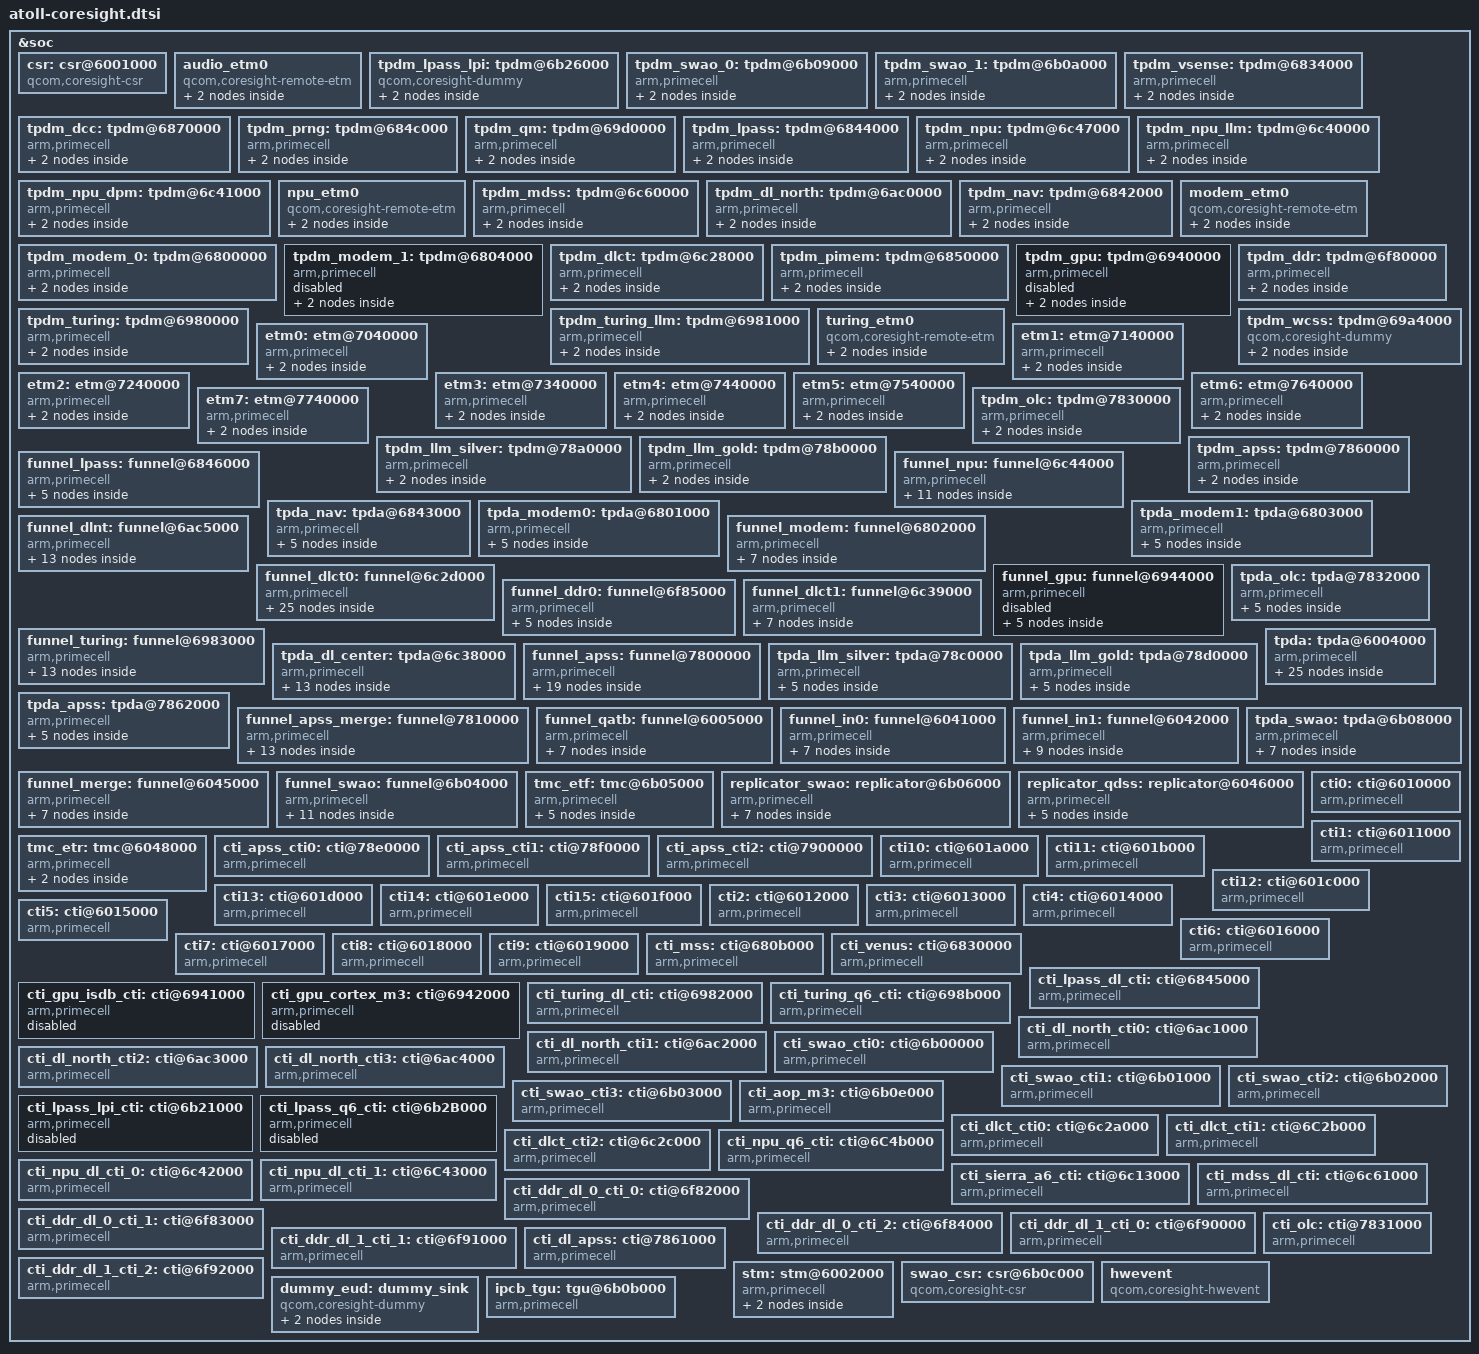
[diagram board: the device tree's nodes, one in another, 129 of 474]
/* Copyright (c) 2019, The Linux Foundation. All rights reserved.
 *
 * This program is free software; you can redistribute it and/or modify
 * it under the terms of the GNU General Public License version 2 and
 * only version 2 as published by the Free Software Foundation.
 *
 * This program is distributed in the hope that it will be useful,
 * but WITHOUT ANY WARRANTY; without even the implied warranty of
 * MERCHANTABILITY or FITNESS FOR A PARTICULAR PURPOSE.  See the
 * GNU General Public License for more details.
 */

&soc {
	csr: csr@6001000 {
		compatible = "qcom,coresight-csr";
		reg = <0x6001000 0x1000>;
		reg-names = "csr-base";

		coresight-name = "coresight-csr";

		qcom,usb-bam-support;
		qcom,hwctrl-set-support;
		qcom,set-byte-cntr-support;
		qcom,blk-size = <1>;
	};

	audio_etm0: audio_etm0 {
		compatible = "qcom,coresight-remote-etm";
		coresight-name = "coresight-audio-etm0";

		qcom,inst-id = <5>;

		port {
			audio_etm0_out_funnel_swao: endpoint {
				remote-endpoint =
				<&funnel_swao_in_audio_etm0>;
			};
		};
	};

	tpdm_lpass_lpi: tpdm@6b26000 {
		compatible = "qcom,coresight-dummy";

		coresight-name = "coresight-tpdm-lpass-lpi";
		qcom,dummy-source;

		port {
			tpdm_lpss_lpi_out_funnel_swao: endpoint {
			remote-endpoint = <&funnel_swao_in_tpdm_lpass_lpi>;
			};
		};
	};

	tpdm_swao_0: tpdm@6b09000 {
		compatible = "arm,primecell";
		arm,primecell-periphid = <0x0003b968>;
		reg = <0x6b09000 0x1000>;
		reg-names = "tpdm-base";

		coresight-name = "coresight-tpdm-swao-0";

		clocks = <&clock_aop QDSS_CLK>;
		clock-names = "apb_pclk";
		port {
			tpdm_swao_0_out_tpda_swao0: endpoint {
				remote-endpoint =
				<&tpda_swao0_in_tpdm_swao_0>;
			};
		};
	};

	tpdm_swao_1: tpdm@6b0a000 {
		compatible = "arm,primecell";
		arm,primecell-periphid = <0x0003b968>;
		reg = <0x6b0a000 0x1000>;
		reg-names = "tpdm-base";

		coresight-name = "coresight-tpdm-swao-1";

		clocks = <&clock_aop QDSS_CLK>;
		clock-names = "apb_pclk";
		port {
			tpdm_swao_1_out_tpda_swao1: endpoint {
				remote-endpoint =
				<&tpda_swao1_in_tpdm_swao_1>;
			};
		};
	};

	tpdm_vsense: tpdm@6834000 {
		compatible = "arm,primecell";
		arm,primecell-periphid = <0x0003b968>;
		reg = <0x6834000 0x1000>;
		reg-names = "tpdm-base";

		coresight-name = "coresight-tpdm-vsense";

		clocks = <&clock_aop QDSS_CLK>;
		clock-names = "apb_pclk";
		port {
			tpdm_vsense_out_tpda21: endpoint {
				remote-endpoint =
				<&tpda21_in_tpdm_vsense>;
			};
		};
	};

	tpdm_dcc: tpdm@6870000 {
		compatible = "arm,primecell";
		arm,primecell-periphid = <0x0003b968>;
		reg = <0x6870000 0x1000>;
		reg-names = "tpdm-base";

		qcom,hw-enable-check;
		coresight-name = "coresight-tpdm-dcc";

		clocks = <&clock_aop QDSS_CLK>;
		clock-names = "apb_pclk";
		port {
			tpdm_dcc_out_tpda22: endpoint {
				remote-endpoint =
				<&tpda22_in_tpdm_dcc>;
			};
		};
	};

	tpdm_prng: tpdm@684c000 {
		compatible = "arm,primecell";
		arm,primecell-periphid = <0x0003b968>;
		reg = <0x684c000 0x1000>;
		reg-names = "tpdm-base";

		coresight-name = "coresight-tpdm-prng";

		clocks = <&clock_aop QDSS_CLK>;
		clock-names = "apb_pclk";
		port {
			tpdm_prng_out_tpda23: endpoint {
				remote-endpoint =
				<&tpda23_in_tpdm_prng>;
			};
		};
	};

	tpdm_qm: tpdm@69d0000 {
		compatible = "arm,primecell";
		arm,primecell-periphid = <0x0003b968>;
		reg = <0x69d0000 0x1000>;
		reg-names = "tpdm-base";

		coresight-name = "coresight-tpdm-qm";

		clocks = <&clock_aop QDSS_CLK>;
		clock-names = "apb_pclk";
		port {
			tpdm_qm_out_tpda24: endpoint {
				remote-endpoint =
				<&tpda24_in_tpdm_qm>;
			};
		};
	};

	tpdm_lpass: tpdm@6844000 {
		compatible = "arm,primecell";
		arm,primecell-periphid = <0x0003b968>;
		reg = <0x6844000 0x1000>;
		reg-names = "tpdm-base";

		qcom,msr-fix-req;
		coresight-name = "coresight-tpdm-lpass";

		clocks = <&clock_aop QDSS_CLK>;
		clock-names = "apb_pclk";
		port {
			tpdm_lpass_out_funnel_lpass: endpoint {
				remote-endpoint =
				<&funnel_lpass_in_tpdm_lpass>;
			};
		};
	};

	tpdm_npu: tpdm@6c47000 {
		compatible = "arm,primecell";
		arm,primecell-periphid = <0x0003b968>;
		reg = <0x6c47000 0x1000>;
		reg-names = "tpdm-base";

		coresight-name = "coresight-tpdm-npu";

		clocks = <&clock_aop QDSS_CLK>;
		clock-names = "apb_pclk";
		port {
			tpdm_npu_out_funnel_npu: endpoint {
				remote-endpoint =
				<&funnel_npu_in_tpdm_npu>;
			};
		};
	};

	tpdm_npu_llm: tpdm@6c40000 {
		compatible = "arm,primecell";
		arm,primecell-periphid = <0x0003b968>;
		reg = <0x6c40000 0x1000>;
		reg-names = "tpdm-base";

		coresight-name = "coresight-tpdm-npu-llm";

		clocks = <&clock_aop QDSS_CLK>,
				<&clock_gcc GCC_NPU_AXI_CLK>,
				<&clock_gcc GCC_NPU_CFG_AHB_CLK>,
				<&clock_npucc NPU_CC_XO_CLK>,
				<&clock_npucc NPU_CC_CORE_CLK>,
				<&clock_npucc NPU_CC_CORE_CLK_SRC>;

		clock-names = "apb_pclk",
				"npu_axi_clk",
				"npu_cfg_ahb_clk",
				"npu_cc_xo_clk",
				"npu_core_clk",
				"npu_core_clk_src";

		qcom,proxy-clks = "npu_axi_clk",
				"npu_cfg_ahb_clk",
				"npu_cc_xo_clk",
				"npu_core_clk",
				"npu_core_clk_src";

		vdd-supply = <&npu_core_gdsc>;
		vdd_cx-supply = <&VDD_CX_LEVEL>;
		qcom,proxy-regs ="vdd", "vdd_cx";
		port {
			tpdm_npu_llm_out_funnel_npu: endpoint {
				remote-endpoint =
				<&funnel_npu_in_tpdm_npu_llm>;
			};
		};
	};

	tpdm_npu_dpm: tpdm@6c41000 {
		compatible = "arm,primecell";
		arm,primecell-periphid = <0x0003b968>;
		reg = <0x6c41000 0x1000>;
		reg-names = "tpdm-base";

		coresight-name = "coresight-tpdm-npu-dpm";

		clocks = <&clock_aop QDSS_CLK>;
		clock-names = "apb_pclk";
		port {
			tpdm_npu_dpm_out_funnel_npu: endpoint {
				remote-endpoint =
				<&funnel_npu_in_tpdm_npu_dpm>;
			};
		};
	};

	npu_etm0: npu_etm0 {
		compatible = "qcom,coresight-remote-etm";
		coresight-name = "coresight-npu-etm0";

		qcom,inst-id = <14>;

		port {
			npu_etm0_out_funnel_npu: endpoint {
				remote-endpoint =
				<&funnel_npu_in_npu_etm0>;
			};
		};
	};

	tpdm_mdss: tpdm@6c60000 {
		compatible = "arm,primecell";
		arm,primecell-periphid = <0x0003b968>;
		reg = <0x6c60000 0x1000>;
		reg-names = "tpdm-base";

		coresight-name = "coresight-tpdm-mdss";

		clocks = <&clock_aop QDSS_CLK>;
		clock-names = "apb_pclk";
		port {
			tpdm_mdss_out_funnel_dlnt: endpoint {
				remote-endpoint =
				<&funnel_dlnt_in_tpdm_mdss>;
			};
		};
	};

	tpdm_dl_north: tpdm@6ac0000 {
		compatible = "arm,primecell";
		arm,primecell-periphid = <0x0003b968>;
		reg = <0x6ac0000 0x1000>;
		reg-names = "tpdm-base";

		coresight-name = "coresight-tpdm-dl-north";

		clocks = <&clock_aop QDSS_CLK>;
		clock-names = "apb_pclk";
		port {
			tpdm_dl_north_out_funnel_dlnt: endpoint {
				remote-endpoint =
				<&funnel_dlnt_in_tpdm_dl_north>;
			};
		};
	};

	tpdm_nav: tpdm@6842000 {
		compatible = "arm,primecell";
		arm,primecell-periphid = <0x0003b968>;
		reg = <0x6842000 0x1000>;
		reg-names = "tpdm-base";

		coresight-name = "coresight-tpdm-nav";

		clocks = <&clock_aop QDSS_CLK>;
		clock-names = "apb_pclk";
		port {
			tpdm_nav_out_tpda_nav0: endpoint {
				remote-endpoint =
				<&tpda_nav0_in_tpdm_nav>;
			};
		};
	};

	modem_etm0: modem_etm0 {
		compatible = "qcom,coresight-remote-etm";
		coresight-name = "coresight-modem-etm0";

		qcom,inst-id = <2>;

		port {
			modem_etm0_out_funnel_dlnt: endpoint {
				remote-endpoint =
				<&funnel_dlnt_in_modem_etm0>;
			};
		};
	};

	tpdm_modem_0: tpdm@6800000 {
		compatible = "arm,primecell";
		arm,primecell-periphid = <0x0003b968>;
		reg = <0x6800000 0x1000>;
		reg-names = "tpdm-base";

		coresight-name = "coresight-tpdm-modem-0";

		clocks = <&clock_aop QDSS_CLK>;
		clock-names = "apb_pclk";
		port {
			tpdm_modem_0_out_tpda_modem0: endpoint {
				remote-endpoint =
				<&tpda_modem0_in_tpdm_modem_0>;
			};
		};
	};

	tpdm_modem_1: tpdm@6804000 {
		compatible = "arm,primecell";
		arm,primecell-periphid = <0x0003b968>;
		reg = <0x6804000 0x1000>;
		reg-names = "tpdm-base";

		status = "disabled";
		coresight-name = "coresight-tpdm-modem-1";

		clocks = <&clock_aop QDSS_CLK>;
		clock-names = "apb_pclk";
		port {
			tpdm_modem_1_out_tpda_modem1: endpoint {
				remote-endpoint =
				<&tpda_modem1_in_tpdm_modem_1>;
			};
		};
	};

	tpdm_dlct: tpdm@6c28000 {
		compatible = "arm,primecell";
		arm,primecell-periphid = <0x0003b968>;
		reg = <0x6c28000 0x1000>;
		reg-names = "tpdm-base";

		coresight-name = "coresight-tpdm-dlct";

		clocks = <&clock_aop QDSS_CLK>;
		clock-names = "apb_pclk";
		port {
			tpdm_dlct_out_funnel_dlct0: endpoint {
				remote-endpoint =
				<&funnel_dlct0_in_tpdm_dlct>;
			};
		};
	};

	tpdm_pimem: tpdm@6850000 {
		compatible = "arm,primecell";
		arm,primecell-periphid = <0x0003b968>;
		reg = <0x6850000 0x1000>;
		reg-names = "tpdm-base";

		coresight-name = "coresight-tpdm-pimem";

		clocks = <&clock_aop QDSS_CLK>;
		clock-names = "apb_pclk";
		port {
			tpdm_pimem_out_tpda_dl_center16: endpoint {
				remote-endpoint =
				<&tpda_dl_center16_in_tpdm_pimem>;
			};
		};
	};

	tpdm_gpu: tpdm@6940000 {
		compatible = "arm,primecell";
		arm,primecell-periphid = <0x0003b968>;
		reg = <0x6940000 0x1000>;
		reg-names = "tpdm-base";

		coresight-name = "coresight-tpdm-gpu";
		status = "disabled";

		clocks = <&clock_aop QDSS_CLK>;
		clock-names = "apb_pclk";
		port {
			tpdm_gpu_out_funnel_gpu: endpoint {
				remote-endpoint =
				<&funnel_gpu_in_tpdm_gpu>;
			};
		};
	};

	tpdm_ddr: tpdm@6f80000 {
		compatible = "arm,primecell";
		arm,primecell-periphid = <0x0003b968>;
		reg = <0x6f80000 0x1000>;
		reg-names = "tpdm-base";

		coresight-name = "coresight-tpdm-ddr";
		qcom,msr-fix-req;

		clocks = <&clock_aop QDSS_CLK>;
		clock-names = "apb_pclk";
		port {
			tpdm_ddr_out_funnel_ddr0: endpoint {
				remote-endpoint =
				<&funnel_ddr0_in_tpdm_ddr>;
			};
		};
	};

	tpdm_turing: tpdm@6980000 {
		compatible = "arm,primecell";
		arm,primecell-periphid = <0x0003b968>;
		reg = <0x6980000 0x1000>;
		reg-names = "tpdm-base";

		coresight-name = "coresight-tpdm-turing";

		clocks = <&clock_aop QDSS_CLK>;
		clock-names = "apb_pclk";
		port {
			tpdm_turing_out_funnel_turing: endpoint {
				remote-endpoint =
				<&funnel_turing_in_tpdm_turing>;
			};
		};
	};

	tpdm_turing_llm: tpdm@6981000 {
		compatible = "arm,primecell";
		arm,primecell-periphid = <0x0003b968>;
		reg = <0x6981000 0x1000>;
		reg-names = "tpdm-base";

		coresight-name = "coresight-tpdm-turing-llm";

		clocks = <&clock_aop QDSS_CLK>;
		clock-names = "apb_pclk";
		port {
			tpdm_turing_llm_out_funnel_turing: endpoint {
				remote-endpoint =
				<&funnel_turing_in_tpdm_turing_llm>;
			};
		};
	};

	turing_etm0: turing_etm0 {
		compatible = "qcom,coresight-remote-etm";
		coresight-name = "coresight-turing-etm0";

		qcom,inst-id = <13>;

		port {
			turing_etm0_out_funnel_turing: endpoint {
				remote-endpoint =
				<&funnel_turing_in_turing_etm0>;
			};
		};
	};

	tpdm_wcss: tpdm@69a4000 {
		compatible = "qcom,coresight-dummy";

		coresight-name = "coresight-tpdm-wcss";
		qcom,dummy-source;

		port {
			tpdm_wcss_out_funnel_in1: endpoint {
				remote-endpoint =
				<&funnel_in1_in_tpdm_wcss>;
			};
		};
	};

	etm0: etm@7040000 {
		compatible = "arm,primecell";
		arm,primecell-periphid = <0x000bb95d>;
		reg = <0x7040000 0x1000>;
		cpu = <&CPU0>;

		coresight-name = "coresight-etm0";

		qcom,tupwr-disable;
		clocks = <&clock_aop QDSS_CLK>;
		clock-names = "apb_pclk";
		port {
			etm0_out_funnel_apss: endpoint {
				remote-endpoint =
				<&funnel_apss_in_etm0>;
			};
		};
	};

	etm1: etm@7140000 {
		compatible = "arm,primecell";
		arm,primecell-periphid = <0x000bb95d>;
		reg = <0x7140000 0x1000>;
		cpu = <&CPU1>;

		coresight-name = "coresight-etm1";

		qcom,tupwr-disable;
		clocks = <&clock_aop QDSS_CLK>;
		clock-names = "apb_pclk";
		port {
			etm1_out_funnel_apss: endpoint {
				remote-endpoint =
				<&funnel_apss_in_etm1>;
			};
		};
	};

	etm2: etm@7240000 {
		compatible = "arm,primecell";
		arm,primecell-periphid = <0x000bb95d>;
		reg = <0x7240000 0x1000>;
		cpu = <&CPU2>;

		qcom,tupwr-disable;
		coresight-name = "coresight-etm2";

		clocks = <&clock_aop QDSS_CLK>;
		clock-names = "apb_pclk";
		port {
			etm2_out_funnel_apss: endpoint {
				remote-endpoint =
				<&funnel_apss_in_etm2>;
			};
		};
	};

	etm3: etm@7340000 {
		compatible = "arm,primecell";
		arm,primecell-periphid = <0x000bb95d>;
		reg = <0x7340000 0x1000>;
		cpu = <&CPU3>;

		qcom,tupwr-disable;
		coresight-name = "coresight-etm3";

		clocks = <&clock_aop QDSS_CLK>;
		clock-names = "apb_pclk";
		port {
			etm3_out_funnel_apss: endpoint {
				remote-endpoint =
				<&funnel_apss_in_etm3>;
			};
		};
	};

	etm4: etm@7440000 {
		compatible = "arm,primecell";
		arm,primecell-periphid = <0x000bb95d>;
		reg = <0x7440000 0x1000>;
		cpu = <&CPU4>;

		coresight-name = "coresight-etm4";

		qcom,tupwr-disable;
		clocks = <&clock_aop QDSS_CLK>;
		clock-names = "apb_pclk";
		port {
			etm4_out_funnel_apss: endpoint {
				remote-endpoint =
				<&funnel_apss_in_etm4>;
			};
		};
	};

	etm5: etm@7540000 {
		compatible = "arm,primecell";
		arm,primecell-periphid = <0x000bb95d>;
		reg = <0x7540000 0x1000>;
		cpu = <&CPU5>;

		coresight-name = "coresight-etm5";

		qcom,tupwr-disable;
		clocks = <&clock_aop QDSS_CLK>;
		clock-names = "apb_pclk";
		port {
			etm5_out_funnel_apss: endpoint {
				remote-endpoint =
				<&funnel_apss_in_etm5>;
			};
		};
	};

	etm6: etm@7640000 {
		compatible = "arm,primecell";
		arm,primecell-periphid = <0x000bb95d>;
		reg = <0x7640000 0x1000>;
		cpu = <&CPU6>;

		coresight-name = "coresight-etm6";

		qcom,tupwr-disable;
		clocks = <&clock_aop QDSS_CLK>;
		clock-names = "apb_pclk";
		port {
			etm6_out_funnel_apss: endpoint {
				remote-endpoint =
				<&funnel_apss_in_etm6>;
			};
		};
	};

	etm7: etm@7740000 {
		compatible = "arm,primecell";
		arm,primecell-periphid = <0x000bb95d>;
		reg = <0x7740000 0x1000>;
		cpu = <&CPU7>;

		coresight-name = "coresight-etm7";

		qcom,tupwr-disable;
		clocks = <&clock_aop QDSS_CLK>;
		clock-names = "apb_pclk";
		port {
			etm7_out_funnel_apss: endpoint {
				remote-endpoint =
				<&funnel_apss_in_etm7>;
			};
		};
	};

	tpdm_olc: tpdm@7830000 {
		compatible = "arm,primecell";
		arm,primecell-periphid = <0x0003b968>;
		reg = <0x7830000 0x1000>;
		reg-names = "tpdm-base";

		coresight-name = "coresight-tpdm-olc";

		clocks = <&clock_aop QDSS_CLK>;
		clock-names = "apb_pclk";
		port {
			tpdm_olc_out_tpda_olc0: endpoint {
				remote-endpoint =
				<&tpda_olc0_in_tpdm_olc>;
			};
		};
	};

	tpdm_llm_silver: tpdm@78a0000 {
		compatible = "arm,primecell";
		arm,primecell-periphid = <0x0003b968>;
		reg = <0x78a0000 0x1000>;
		reg-names = "tpdm-base";

		coresight-name = "coresight-tpdm-llm-silver";

		clocks = <&clock_aop QDSS_CLK>;
		clock-names = "apb_pclk";
		port {
			tpdm_llm_silver_out_tpda_llm_silver0: endpoint {
				remote-endpoint =
				<&tpda_llm_silver0_in_tpdm_llm_silver>;
			};
		};
	};

	tpdm_llm_gold: tpdm@78b0000 {
		compatible = "arm,primecell";
		arm,primecell-periphid = <0x0003b968>;
		reg = <0x78b0000 0x1000>;
		reg-names = "tpdm-base";

		coresight-name = "coresight-tpdm-llm-gold";

		clocks = <&clock_aop QDSS_CLK>;
		clock-names = "apb_pclk";
		port {
			tpdm_llm_gold_out_tpda_llm_gold0: endpoint {
				remote-endpoint =
				<&tpda_llm_gold0_in_tpdm_llm_gold>;
			};
		};
	};

	tpdm_apss: tpdm@7860000 {
		compatible = "arm,primecell";
		arm,primecell-periphid = <0x0003b968>;
		reg = <0x7860000 0x1000>;
		reg-names = "tpdm-base";

		coresight-name = "coresight-tpdm-apss";

		clocks = <&clock_aop QDSS_CLK>;
		clock-names = "apb_pclk";
		port {
			tpdm_apss_out_tpda_apss0: endpoint {
				remote-endpoint =
				<&tpda_apss0_in_tpdm_apss>;
			};
		};
	};

	funnel_lpass: funnel@6846000 {
		compatible = "arm,primecell";
		arm,primecell-periphid = <0x0003b908>;
		reg = <0x6846000 0x1000>;
		reg-names = "funnel-base";

		coresight-name = "coresight-funnel-lpass";

		clocks = <&clock_aop QDSS_CLK>;
		clock-names = "apb_pclk";
		ports {
			#address-cells = <1>;
			#size-cells = <0>;
			port@0 {
				reg = <0>;
				funnel_lpass_out_funnel_dlct0: endpoint {
					remote-endpoint =
					<&funnel_dlct0_in_funnel_lpass>;
				};
			};

			port@1 {
				reg = <0>;
				funnel_lpass_in_tpdm_lpass: endpoint {
					slave-mode;
					remote-endpoint =
					<&tpdm_lpass_out_funnel_lpass>;
				};
			};

		};
	};

	funnel_npu: funnel@6c44000 {
		compatible = "arm,primecell";
		arm,primecell-periphid = <0x0003b908>;
		reg = <0x6c44000 0x1000>;
		reg-names = "funnel-base";

		coresight-name = "coresight-funnel-npu";

		clocks = <&clock_aop QDSS_CLK>;
		clock-names = "apb_pclk";
		ports {
			#address-cells = <1>;
			#size-cells = <0>;
			port@0 {
				reg = <0>;
				funnel_npu_out_funnel_dlct0: endpoint {
					remote-endpoint =
					<&funnel_dlct0_in_funnel_npu>;
				};
			};

			port@1 {
				reg = <0>;
				funnel_npu_in_tpdm_npu: endpoint {
					slave-mode;
					remote-endpoint =
					<&tpdm_npu_out_funnel_npu>;
				};
			};

			port@2 {
				reg = <1>;
				funnel_npu_in_tpdm_npu_llm: endpoint {
					slave-mode;
					remote-endpoint =
					<&tpdm_npu_llm_out_funnel_npu>;
				};
			};

			port@3 {
				reg = <2>;
				funnel_npu_in_tpdm_npu_dpm: endpoint {
					slave-mode;
					remote-endpoint =
					<&tpdm_npu_dpm_out_funnel_npu>;
				};
			};

			port@4 {
				reg = <3>;
				funnel_npu_in_npu_etm0: endpoint {
					slave-mode;
					remote-endpoint =
					<&npu_etm0_out_funnel_npu>;
				};
			};

		};
	};

	tpda_nav: tpda@6843000 {
		compatible = "arm,primecell";
		arm,primecell-periphid = <0x0003b969>;
		reg = <0x6843000 0x1000>;
		reg-names = "tpda-base";

		coresight-name = "coresight-tpda-nav";
		qcom,tpda-atid = <68>;
		qcom,cmb-elem-size = <0 32>;

		clocks = <&clock_aop QDSS_CLK>;
		clock-names = "apb_pclk";
		ports {
			#address-cells = <1>;
			#size-cells = <0>;
			port@0 {
				reg = <0>;
				tpda_nav_out_funnel_dlnt: endpoint {
					remote-endpoint =
					<&funnel_dlnt_in_tpda_nav>;
				};
			};

			port@1 {
				reg = <0>;
				tpda_nav0_in_tpdm_nav: endpoint {
					slave-mode;
					remote-endpoint =
					<&tpdm_nav_out_tpda_nav0>;
				};
			};

		};
	};

	tpda_modem0: tpda@6801000 {
		compatible = "arm,primecell";
		arm,primecell-periphid = <0x0003b969>;
		reg = <0x6801000 0x1000>;
		reg-names = "tpda-base";

		coresight-name = "coresight-tpda-modem0";
		qcom,tpda-atid = <67>;
		qcom,dsb-elem-size = <0 32>;
		qcom,cmb-elem-size = <0 64>;

		clocks = <&clock_aop QDSS_CLK>;
		clock-names = "apb_pclk";
		ports {
			#address-cells = <1>;
			#size-cells = <0>;
			port@0 {
				reg = <0>;
				tpda_modem0_out_funnel_modem: endpoint {
					remote-endpoint =
					<&funnel_modem_in_tpda_modem0>;
				};
			};

			port@1 {
				reg = <0>;
				tpda_modem0_in_tpdm_modem_0: endpoint {
					slave-mode;
					remote-endpoint =
					<&tpdm_modem_0_out_tpda_modem0>;
				};
			};

		};
	};

	tpda_modem1: tpda@6803000 {
		compatible = "arm,primecell";
		arm,primecell-periphid = <0x0003b969>;
		reg = <0x6803000 0x1000>;
		reg-names = "tpda-base";

		coresight-name = "coresight-tpda-modem1";
		qcom,tpda-atid = <98>;
		qcom,dsb-elem-size = <0 32>;
		qcom,cmb-elem-size = <0 64>;

		clocks = <&clock_aop QDSS_CLK>;
		clock-names = "apb_pclk";
		ports {
			#address-cells = <1>;
			#size-cells = <0>;
			port@0 {
				reg = <0>;
				tpda_modem1_out_funnel_modem: endpoint {
					remote-endpoint =
					<&funnel_modem_in_tpda_modem1>;
				};
			};

			port@1 {
				reg = <0>;
				tpda_modem1_in_tpdm_modem_1: endpoint {
					slave-mode;
					remote-endpoint =
					<&tpdm_modem_1_out_tpda_modem1>;
				};
			};

		};
	};

	funnel_modem: funnel@6802000 {
		compatible = "arm,primecell";
		arm,primecell-periphid = <0x0003b908>;
		reg = <0x6802000 0x1000>;
		reg-names = "funnel-base";

		coresight-name = "coresight-funnel-modem";

		clocks = <&clock_aop QDSS_CLK>;
		clock-names = "apb_pclk";
		ports {
			#address-cells = <1>;
			#size-cells = <0>;
			port@0 {
				reg = <0>;
				funnel_modem_out_funnel_dlnt: endpoint {
					remote-endpoint =
					<&funnel_dlnt_in_funnel_modem>;
				};
			};

			port@1 {
				reg = <0>;
				funnel_modem_in_tpda_modem0: endpoint {
					slave-mode;
					remote-endpoint =
					<&tpda_modem0_out_funnel_modem>;
				};
			};

			port@2 {
				reg = <1>;
				funnel_modem_in_tpda_modem1: endpoint {
					slave-mode;
					remote-endpoint =
					<&tpda_modem1_out_funnel_modem>;
				};
			};

		};
	};

	funnel_dlnt: funnel@6ac5000 {
		compatible = "arm,primecell";
		arm,primecell-periphid = <0x0003b908>;
		reg = <0x6ac5000 0x1000>;
		reg-names = "funnel-base";

		coresight-name = "coresight-funnel-dlnt";

		clocks = <&clock_aop QDSS_CLK>;
		clock-names = "apb_pclk";
		ports {
			#address-cells = <1>;
			#size-cells = <0>;
			port@0 {
				reg = <0>;
				funnel_dlnt_out_funnel_dlct0: endpoint {
					remote-endpoint =
					<&funnel_dlct0_in_funnel_dlnt>;
				};
			};

			port@1 {
				reg = <0>;
				funnel_dlnt_in_tpdm_mdss: endpoint {
					slave-mode;
					remote-endpoint =
					<&tpdm_mdss_out_funnel_dlnt>;
				};
			};

			port@2 {
				reg = <1>;
				funnel_dlnt_in_tpdm_dl_north: endpoint {
					slave-mode;
					remote-endpoint =
					<&tpdm_dl_north_out_funnel_dlnt>;
				};
			};

			port@3 {
				reg = <2>;
				funnel_dlnt_in_tpda_nav: endpoint {
					slave-mode;
					remote-endpoint =
					<&tpda_nav_out_funnel_dlnt>;
				};
			};

			port@4 {
				reg = <5>;
				funnel_dlnt_in_modem_etm0: endpoint {
					slave-mode;
					remote-endpoint =
					<&modem_etm0_out_funnel_dlnt>;
				};
			};

			port@5 {
				reg = <6>;
				funnel_dlnt_in_funnel_modem: endpoint {
					slave-mode;
					remote-endpoint =
					<&funnel_modem_out_funnel_dlnt>;
				};
			};

		};
	};

	funnel_dlct0: funnel@6c2d000 {
		compatible = "arm,primecell";
		arm,primecell-periphid = <0x0003b908>;
		reg = <0x6c2d000 0x1000>;
		reg-names = "funnel-base";

		coresight-name = "coresight-funnel-dlct0";

		clocks = <&clock_aop QDSS_CLK>;
		clock-names = "apb_pclk";
		ports {
			#address-cells = <1>;
			#size-cells = <0>;
			port@0 {
				reg = <0>;
				funnel_dlct0_out_tpda2: endpoint {
					remote-endpoint =
					<&tpda2_in_funnel_dlct0>;
					source = <&tpdm_lpass>;
				};
			};

			port@1 {
				reg = <0>;
				funnel_dlct0_out_tpda11: endpoint {
					remote-endpoint =
					<&tpda11_in_funnel_dlct0>;
					source = <&tpdm_npu>;
				};
			};

			port@2 {
				reg = <0>;
				funnel_dlct0_out_tpda12: endpoint {
					remote-endpoint =
					<&tpda12_in_funnel_dlct0>;
					source = <&tpdm_npu_llm>;
				};
			};

			port@3 {
				reg = <0>;
				funnel_dlct0_out_tpda13: endpoint {
					remote-endpoint =
					<&tpda13_in_funnel_dlct0>;
					source = <&tpdm_npu_dpm>;
				};
			};

			port@4 {
				reg = <0>;
				funnel_dlct0_out_tpda14: endpoint {
					remote-endpoint =
					<&tpda14_in_funnel_dlct0>;
					source = <&tpdm_mdss>;
				};
			};

			port@5 {
				reg = <0>;
				funnel_dlct0_out_tpda15: endpoint {
					remote-endpoint =
					<&tpda15_in_funnel_dlct0>;
					source = <&tpdm_dl_north>;
				};
			};

			port@6 {
				reg = <0>;
				funnel_dlct0_out_tpda19: endpoint {
					remote-endpoint =
					<&tpda19_in_funnel_dlct0>;
					source = <&tpdm_dlct>;
				};
			};

			port@7 {
				reg = <0>;
				funnel_dlct0_out_funnel_qatb: endpoint {
					remote-endpoint =
					<&funnel_qatb_in_funnel_dlct0>;
				};
			};

			port@8 {
				reg = <0>;
				funnel_dlct0_in_funnel_lpass: endpoint {
					slave-mode;
					remote-endpoint =
					<&funnel_lpass_out_funnel_dlct0>;
				};
			};

			port@9 {
				reg = <4>;
				funnel_dlct0_in_funnel_npu: endpoint {
					slave-mode;
					remote-endpoint =
					<&funnel_npu_out_funnel_dlct0>;
				};
			};

			port@10 {
				reg = <5>;
				funnel_dlct0_in_funnel_dlnt: endpoint {
					slave-mode;
					remote-endpoint =
					<&funnel_dlnt_out_funnel_dlct0>;
				};
			};

			port@11 {
				reg = <6>;
				funnel_dlct0_in_tpdm_dlct: endpoint {
					slave-mode;
					remote-endpoint =
					<&tpdm_dlct_out_funnel_dlct0>;
				};
			};

		};
	};

	funnel_gpu: funnel@6944000 {
		compatible = "arm,primecell";
		arm,primecell-periphid = <0x0003b908>;
		reg = <0x6944000 0x1000>;
		reg-names = "funnel-base";

		coresight-name = "coresight-funnel-gpu";
		status = "disabled";

		clocks = <&clock_aop QDSS_CLK>;
		clock-names = "apb_pclk";
		ports {
			#address-cells = <1>;
			#size-cells = <0>;
			port@0 {
				reg = <0>;
				funnel_gpu_out_tpda_dl_center: endpoint {
					remote-endpoint =
					<&tpda_dl_center_in_funnel_gpu>;
				};
			};

			port@1 {
				reg = <0>;
				funnel_gpu_in_tpdm_gpu: endpoint {
					slave-mode;
					remote-endpoint =
					<&tpdm_gpu_out_funnel_gpu>;
				};
			};

		};
	};

	funnel_ddr0: funnel@6f85000 {
		compatible = "arm,primecell";
		arm,primecell-periphid = <0x0003b908>;
		reg = <0x6f85000 0x1000>;
		reg-names = "funnel-base";

		coresight-name = "coresight-funnel-ddr0";

		clocks = <&clock_aop QDSS_CLK>;
		clock-names = "apb_pclk";
		ports {
			#address-cells = <1>;
			#size-cells = <0>;
			port@0 {
				reg = <0>;
				funnel_ddr0_out_tpda_dl_center: endpoint {
					remote-endpoint =
					<&tpda_dl_center_in_funnel_ddr0>;
				};
			};

			port@1 {
				reg = <0>;
				funnel_ddr0_in_tpdm_ddr: endpoint {
					slave-mode;
					remote-endpoint =
					<&tpdm_ddr_out_funnel_ddr0>;
				};
			};

		};
	};

	funnel_turing: funnel@6983000 {
		compatible = "arm,primecell";
		arm,primecell-periphid = <0x0003b908>;
		reg = <0x6983000 0x1000>;
		reg-names = "funnel-base";

		coresight-name = "coresight-funnel-turing";

		clocks = <&clock_aop QDSS_CLK>;
		clock-names = "apb_pclk";
		ports {
			#address-cells = <1>;
			#size-cells = <0>;
			port@0 {
				reg = <0>;
				funnel_turing_out_tpda_dl_center5: endpoint {
					remote-endpoint =
					<&tpda_dl_center5_in_funnel_turing>;
					source = <&tpdm_turing>;
				};
			};

			port@1 {
				reg = <0>;
				funnel_turing_out_tpda_dl_center6: endpoint {
					remote-endpoint =
					<&tpda_dl_center6_in_funnel_turing>;
					source = <&tpdm_turing_llm>;
				};
			};

			port@2 {
				reg = <0>;
				funnel_turing_out_funnel_dlct1: endpoint {
					remote-endpoint =
					<&funnel_dlct1_in_funnel_turing>;
				};
			};

			port@3 {
				reg = <0>;
				funnel_turing_in_tpdm_turing: endpoint {
					slave-mode;
					remote-endpoint =
					<&tpdm_turing_out_funnel_turing>;
				};
			};

			port@4 {
				reg = <1>;
				funnel_turing_in_tpdm_turing_llm: endpoint {
					slave-mode;
					remote-endpoint =
					<&tpdm_turing_llm_out_funnel_turing>;
				};
			};

			port@5 {
				reg = <2>;
				funnel_turing_in_turing_etm0: endpoint {
					slave-mode;
					remote-endpoint =
					<&turing_etm0_out_funnel_turing>;
				};
			};

		};
	};

	tpda_dl_center: tpda@6c38000 {
		compatible = "arm,primecell";
		arm,primecell-periphid = <0x0003b969>;
		reg = <0x6c38000 0x1000>;
		reg-names = "tpda-base";

		coresight-name = "coresight-tpda-dl-center";
		qcom,tpda-atid = <78>;
		qcom,dsb-elem-size = <0 32>,
				     <3 32>,
				     <5 32>,
				     <16 32>;
		qcom,cmb-elem-size = <3 32>,
				     <6 32>,
				     <16 64>;

		clocks = <&clock_aop QDSS_CLK>;
		clock-names = "apb_pclk";
		ports {
			#address-cells = <1>;
			#size-cells = <0>;
			port@0 {
				reg = <0>;
				tpda_dl_center_out_funnel_dlct1: endpoint {
					remote-endpoint =
					<&funnel_dlct1_in_tpda_dl_center>;
				};
			};

			port@1 {
				reg = <16>;
				tpda_dl_center16_in_tpdm_pimem: endpoint {
					slave-mode;
					remote-endpoint =
					<&tpdm_pimem_out_tpda_dl_center16>;
				};
			};

			port@2 {
				reg = <0>;
				tpda_dl_center_in_funnel_gpu: endpoint {
					slave-mode;
					remote-endpoint =
					<&funnel_gpu_out_tpda_dl_center>;
				};
			};

			port@3 {
				reg = <3>;
				tpda_dl_center_in_funnel_ddr0: endpoint {
					slave-mode;
					remote-endpoint =
					<&funnel_ddr0_out_tpda_dl_center>;
				};
			};

			port@4 {
				reg = <5>;
				tpda_dl_center5_in_funnel_turing: endpoint {
					slave-mode;
					remote-endpoint =
					<&funnel_turing_out_tpda_dl_center5>;
				};
			};

			port@5 {
				reg = <6>;
				tpda_dl_center6_in_funnel_turing: endpoint {
					slave-mode;
					remote-endpoint =
					<&funnel_turing_out_tpda_dl_center6>;
				};
			};

		};
	};

	funnel_dlct1: funnel@6c39000 {
		compatible = "arm,primecell";
		arm,primecell-periphid = <0x0003b908>;
		reg = <0x6c39000 0x1000>;
		reg-names = "funnel-base";

		coresight-name = "coresight-funnel-dlct1";

		clocks = <&clock_aop QDSS_CLK>;
		clock-names = "apb_pclk";
		ports {
			#address-cells = <1>;
			#size-cells = <0>;
			port@0 {
				reg = <0>;
				funnel_dlct1_out_funnel_in1: endpoint {
					remote-endpoint =
					<&funnel_in1_in_funnel_dlct1>;
				};
			};

			port@1 {
				reg = <0>;
				funnel_dlct1_in_tpda_dl_center: endpoint {
					slave-mode;
					remote-endpoint =
					<&tpda_dl_center_out_funnel_dlct1>;
				};
			};

			port@2 {
				reg = <4>;
				funnel_dlct1_in_funnel_turing: endpoint {
					slave-mode;
					remote-endpoint =
					<&funnel_turing_out_funnel_dlct1>;
				};
			};

		};
	};

	funnel_apss: funnel@7800000 {
		compatible = "arm,primecell";
		arm,primecell-periphid = <0x0003b908>;
		reg = <0x7800000 0x1000>;
		reg-names = "funnel-base";

		coresight-name = "coresight-funnel-apss";

		clocks = <&clock_aop QDSS_CLK>;
		clock-names = "apb_pclk";
		ports {
			#address-cells = <1>;
			#size-cells = <0>;
			port@0 {
				reg = <0>;
				funnel_apss_out_funnel_apss_merge: endpoint {
					remote-endpoint =
					<&funnel_apss_merge_in_funnel_apss>;
				};
			};

			port@1 {
				reg = <0>;
				funnel_apss_in_etm0: endpoint {
					slave-mode;
					remote-endpoint =
					<&etm0_out_funnel_apss>;
				};
			};

			port@2 {
				reg = <1>;
				funnel_apss_in_etm1: endpoint {
					slave-mode;
					remote-endpoint =
					<&etm1_out_funnel_apss>;
				};
			};

			port@3 {
				reg = <2>;
				funnel_apss_in_etm2: endpoint {
					slave-mode;
					remote-endpoint =
					<&etm2_out_funnel_apss>;
				};
			};

			port@4 {
				reg = <3>;
				funnel_apss_in_etm3: endpoint {
					slave-mode;
					remote-endpoint =
					<&etm3_out_funnel_apss>;
				};
			};

			port@5 {
				reg = <4>;
				funnel_apss_in_etm4: endpoint {
					slave-mode;
					remote-endpoint =
					<&etm4_out_funnel_apss>;
				};
			};

			port@6 {
				reg = <5>;
				funnel_apss_in_etm5: endpoint {
					slave-mode;
					remote-endpoint =
					<&etm5_out_funnel_apss>;
				};
			};

			port@7 {
				reg = <6>;
				funnel_apss_in_etm6: endpoint {
					slave-mode;
					remote-endpoint =
					<&etm6_out_funnel_apss>;
				};
			};

			port@8 {
				reg = <7>;
				funnel_apss_in_etm7: endpoint {
					slave-mode;
					remote-endpoint =
					<&etm7_out_funnel_apss>;
				};
			};

		};
	};

	tpda_olc: tpda@7832000 {
		compatible = "arm,primecell";
		arm,primecell-periphid = <0x0003b969>;
		reg = <0x7832000 0x1000>;
		reg-names = "tpda-base";

		coresight-name = "coresight-tpda-olc";
		qcom,tpda-atid = <69>;
		qcom,cmb-elem-size = <0 64>;

		clocks = <&clock_aop QDSS_CLK>;
		clock-names = "apb_pclk";
		ports {
			#address-cells = <1>;
			#size-cells = <0>;
			port@0 {
				reg = <0>;
				tpda_olc_out_funnel_apss_merge: endpoint {
					remote-endpoint =
					<&funnel_apss_merge_in_tpda_olc>;
				};
			};

			port@1 {
				reg = <0>;
				tpda_olc0_in_tpdm_olc: endpoint {
					slave-mode;
					remote-endpoint =
					<&tpdm_olc_out_tpda_olc0>;
				};
			};

		};
	};

	tpda_llm_silver: tpda@78c0000 {
		compatible = "arm,primecell";
		arm,primecell-periphid = <0x0003b969>;
		reg = <0x78c0000 0x1000>;
		reg-names = "tpda-base";

		coresight-name = "coresight-tpda-llm-silver";
		qcom,tpda-atid = <72>;
		qcom,cmb-elem-size = <0 32>;

		clocks = <&clock_aop QDSS_CLK>;
		clock-names = "apb_pclk";
		ports {
			#address-cells = <1>;
			#size-cells = <0>;
			port@0 {
				reg = <0>;
				tpda_silver_out_funnel_apss_merge: endpoint {
					remote-endpoint =
					<&funnel_apss_merge_in_tpda_llm_silver>;
				};
			};

			port@1 {
				reg = <0>;
				tpda_llm_silver0_in_tpdm_llm_silver: endpoint {
					slave-mode;
					remote-endpoint =
					<&tpdm_llm_silver_out_tpda_llm_silver0>;
				};
			};

		};
	};

	tpda_llm_gold: tpda@78d0000 {
		compatible = "arm,primecell";
		arm,primecell-periphid = <0x0003b969>;
		reg = <0x78d0000 0x1000>;
		reg-names = "tpda-base";

		coresight-name = "coresight-tpda-llm-gold";
		qcom,tpda-atid = <73>;
		qcom,cmb-elem-size = <0 32>;

		clocks = <&clock_aop QDSS_CLK>;
		clock-names = "apb_pclk";
		ports {
			#address-cells = <1>;
			#size-cells = <0>;
			port@0 {
				reg = <0>;
				tpda_llm_gold_out_funnel_apss_merge: endpoint {
					remote-endpoint =
					<&funnel_apss_merge_in_tpda_llm_gold>;
				};
			};

			port@1 {
				reg = <0>;
				tpda_llm_gold0_in_tpdm_llm_gold: endpoint {
					slave-mode;
					remote-endpoint =
					<&tpdm_llm_gold_out_tpda_llm_gold0>;
				};
			};

		};
	};

	tpda_apss: tpda@7862000 {
		compatible = "arm,primecell";
		arm,primecell-periphid = <0x0003b969>;
		reg = <0x7862000 0x1000>;
		reg-names = "tpda-base";

		coresight-name = "coresight-tpda-apss";
		qcom,tpda-atid = <66>;
		qcom,dsb-elem-size = <0 32>;

		clocks = <&clock_aop QDSS_CLK>;
		clock-names = "apb_pclk";
		ports {
			#address-cells = <1>;
			#size-cells = <0>;
			port@0 {
				reg = <0>;
				tpda_apss_out_funnel_apss_merge: endpoint {
					remote-endpoint =
					<&funnel_apss_merge_in_tpda_apss>;
				};
			};

			port@1 {
				reg = <0>;
				tpda_apss0_in_tpdm_apss: endpoint {
					slave-mode;
					remote-endpoint =
					<&tpdm_apss_out_tpda_apss0>;
				};
			};

		};
	};

	funnel_apss_merge: funnel@7810000 {
		compatible = "arm,primecell";
		arm,primecell-periphid = <0x0003b908>;
		reg = <0x7810000 0x1000>;
		reg-names = "funnel-base";

		coresight-name = "coresight-funnel-apss-merge";

		clocks = <&clock_aop QDSS_CLK>;
		clock-names = "apb_pclk";
		ports {
			#address-cells = <1>;
			#size-cells = <0>;
			port@0 {
				reg = <0>;
				funnel_apss_merge_out_funnel_in1: endpoint {
					remote-endpoint =
					<&funnel_in1_in_funnel_apss_merge>;
				};
			};

			port@1 {
				reg = <0>;
				funnel_apss_merge_in_funnel_apss: endpoint {
					slave-mode;
					remote-endpoint =
					<&funnel_apss_out_funnel_apss_merge>;
				};
			};

			port@2 {
				reg = <2>;
				funnel_apss_merge_in_tpda_olc: endpoint {
					slave-mode;
					remote-endpoint =
					<&tpda_olc_out_funnel_apss_merge>;
				};
			};

			port@3 {
				reg = <3>;
				funnel_apss_merge_in_tpda_llm_silver: endpoint {
					slave-mode;
					remote-endpoint =
					<&tpda_silver_out_funnel_apss_merge>;
				};
			};

			port@4 {
				reg = <4>;
				funnel_apss_merge_in_tpda_llm_gold: endpoint {
					slave-mode;
					remote-endpoint =
					<&tpda_llm_gold_out_funnel_apss_merge>;
				};
			};

			port@5 {
				reg = <5>;
				funnel_apss_merge_in_tpda_apss: endpoint {
					slave-mode;
					remote-endpoint =
					<&tpda_apss_out_funnel_apss_merge>;
				};
			};

		};
	};

	tpda: tpda@6004000 {
		compatible = "arm,primecell";
		arm,primecell-periphid = <0x0003b969>;
		reg = <0x6004000 0x1000>;
		reg-names = "tpda-base";

		coresight-name = "coresight-tpda";
		qcom,tpda-atid = <65>;
		qcom,bc-elem-size = <16 32>,
				    <24 32>,
				    <25 32>;
		qcom,tc-elem-size = <16 32>,
				    <25 32>;
		qcom,dsb-elem-size = <2 32>,
				     <11 32>,
				     <14 32>,
				     <15 32>,
				     <19 32>,
				     <24 32>;
		qcom,cmb-elem-size = <11 32>,
				     <12 32>,
				     <13 64>,
				     <14 32>,
				     <21 32>,
				     <22 32>,
				     <23 32>;

		clocks = <&clock_aop QDSS_CLK>;
		clock-names = "apb_pclk";
		ports {
			#address-cells = <1>;
			#size-cells = <0>;
			port@0 {
				reg = <0>;
				tpda_out_funnel_qatb: endpoint {
					remote-endpoint =
					<&funnel_qatb_in_tpda>;
				};
			};

			port@1 {
				reg = <21>;
				tpda21_in_tpdm_vsense: endpoint {
					slave-mode;
					remote-endpoint =
					<&tpdm_vsense_out_tpda21>;
				};
			};

			port@2 {
				reg = <22>;
				tpda22_in_tpdm_dcc: endpoint {
					slave-mode;
					remote-endpoint =
					<&tpdm_dcc_out_tpda22>;
				};
			};

			port@3 {
				reg = <23>;
				tpda23_in_tpdm_prng: endpoint {
					slave-mode;
					remote-endpoint =
					<&tpdm_prng_out_tpda23>;
				};
			};

			port@4 {
				reg = <24>;
				tpda24_in_tpdm_qm: endpoint {
					slave-mode;
					remote-endpoint =
					<&tpdm_qm_out_tpda24>;
				};
			};

			port@5 {
				reg = <2>;
				tpda2_in_funnel_dlct0: endpoint {
					slave-mode;
					remote-endpoint =
					<&funnel_dlct0_out_tpda2>;
				};
			};

			port@6 {
				reg = <11>;
				tpda11_in_funnel_dlct0: endpoint {
					slave-mode;
					remote-endpoint =
					<&funnel_dlct0_out_tpda11>;
				};
			};

			port@7 {
				reg = <12>;
				tpda12_in_funnel_dlct0: endpoint {
					slave-mode;
					remote-endpoint =
					<&funnel_dlct0_out_tpda12>;
				};
			};

			port@8 {
				reg = <13>;
				tpda13_in_funnel_dlct0: endpoint {
					slave-mode;
					remote-endpoint =
					<&funnel_dlct0_out_tpda13>;
				};
			};

			port@9 {
				reg = <14>;
				tpda14_in_funnel_dlct0: endpoint {
					slave-mode;
					remote-endpoint =
					<&funnel_dlct0_out_tpda14>;
				};
			};

			port@10 {
				reg = <15>;
				tpda15_in_funnel_dlct0: endpoint {
					slave-mode;
					remote-endpoint =
					<&funnel_dlct0_out_tpda15>;
				};
			};

			port@11 {
				reg = <19>;
				tpda19_in_funnel_dlct0: endpoint {
					slave-mode;
					remote-endpoint =
					<&funnel_dlct0_out_tpda19>;
				};
			};

		};
	};

	funnel_qatb: funnel@6005000 {
		compatible = "arm,primecell";
		arm,primecell-periphid = <0x0003b908>;
		reg = <0x6005000 0x1000>;
		reg-names = "funnel-base";

		coresight-name = "coresight-funnel-qatb";

		clocks = <&clock_aop QDSS_CLK>;
		clock-names = "apb_pclk";
		ports {
			#address-cells = <1>;
			#size-cells = <0>;
			port@0 {
				reg = <0>;
				funnel_qatb_out_funnel_in0: endpoint {
					remote-endpoint =
					<&funnel_in0_in_funnel_qatb>;
				};
			};

			port@1 {
				reg = <0>;
				funnel_qatb_in_tpda: endpoint {
					slave-mode;
					remote-endpoint =
					<&tpda_out_funnel_qatb>;
				};
			};

			port@2 {
				reg = <3>;
				funnel_qatb_in_funnel_dlct0: endpoint {
					slave-mode;
					remote-endpoint =
					<&funnel_dlct0_out_funnel_qatb>;
				};
			};

		};
	};

	funnel_in0: funnel@6041000 {
		compatible = "arm,primecell";
		arm,primecell-periphid = <0x0003b908>;
		reg = <0x6041000 0x1000>;
		reg-names = "funnel-base";

		coresight-name = "coresight-funnel-in0";

		clocks = <&clock_aop QDSS_CLK>;
		clock-names = "apb_pclk";
		ports {
			#address-cells = <1>;
			#size-cells = <0>;
			port@0 {
				reg = <0>;
				funnel_in0_out_funnel_merge: endpoint {
					remote-endpoint =
					<&funnel_merge_in_funnel_in0>;
				};
			};

			port@1 {
				reg = <6>;
				funnel_in0_in_funnel_qatb: endpoint {
					slave-mode;
					remote-endpoint =
					<&funnel_qatb_out_funnel_in0>;
				};
			};

			port@2 {
				reg = <7>;
				funnel_in0_in_stm: endpoint {
					slave-mode;
					remote-endpoint =
					<&stm_out_funnel_in0>;
				};
			};

		};
	};

	funnel_in1: funnel@6042000 {
		compatible = "arm,primecell";
		arm,primecell-periphid = <0x0003b908>;
		reg = <0x6042000 0x1000>;
		reg-names = "funnel-base";

		coresight-name = "coresight-funnel-in1";

		clocks = <&clock_aop QDSS_CLK>;
		clock-names = "apb_pclk";
		ports {
			#address-cells = <1>;
			#size-cells = <0>;
			port@0 {
				reg = <0>;
				funnel_in1_out_funnel_merge: endpoint {
					remote-endpoint =
					<&funnel_merge_in_funnel_in1>;
				};
			};

			port@1 {
				reg = <1>;
				funnel_in1_in_funnel_dlct1: endpoint {
					slave-mode;
					remote-endpoint =
					<&funnel_dlct1_out_funnel_in1>;
				};
			};

			port@2 {
				reg = <2>;
				funnel_in1_in_tpdm_wcss: endpoint {
					slave-mode;
					remote-endpoint =
					<&tpdm_wcss_out_funnel_in1>;
				};
			};

			port@3 {
				reg = <4>;
				funnel_in1_in_funnel_apss_merge: endpoint {
					slave-mode;
					remote-endpoint =
					<&funnel_apss_merge_out_funnel_in1>;
				};
			};

		};
	};

	funnel_merge: funnel@6045000 {
		compatible = "arm,primecell";
		arm,primecell-periphid = <0x0003b908>;
		reg = <0x6045000 0x1000>;
		reg-names = "funnel-base";

		coresight-name = "coresight-funnel-merge";

		clocks = <&clock_aop QDSS_CLK>;
		clock-names = "apb_pclk";
		ports {
			#address-cells = <1>;
			#size-cells = <0>;
			port@0 {
				reg = <0>;
				funnel_merge_out_funnel_swao: endpoint {
					remote-endpoint =
					<&funnel_swao_in_funnel_merge>;
				};
			};

			port@1 {
				reg = <0>;
				funnel_merge_in_funnel_in0: endpoint {
					slave-mode;
					remote-endpoint =
					<&funnel_in0_out_funnel_merge>;
				};
			};

			port@2 {
				reg = <1>;
				funnel_merge_in_funnel_in1: endpoint {
					slave-mode;
					remote-endpoint =
					<&funnel_in1_out_funnel_merge>;
				};
			};

		};
	};

	tpda_swao: tpda@6b08000 {
		compatible = "arm,primecell";
		arm,primecell-periphid = <0x0003b969>;
		reg = <0x6b08000 0x1000>;
		reg-names = "tpda-base";

		coresight-name = "coresight-tpda-swao";
		qcom,tpda-atid = <71>;
		qcom,dsb-elem-size = <1 32>;
		qcom,cmb-elem-size = <0 64>;

		clocks = <&clock_aop QDSS_CLK>;
		clock-names = "apb_pclk";
		ports {
			#address-cells = <1>;
			#size-cells = <0>;
			port@0 {
				reg = <0>;
				tpda_swao_out_funnel_swao: endpoint {
					remote-endpoint =
					<&funnel_swao_in_tpda_swao>;
				};
			};

			port@1 {
				reg = <0>;
				tpda_swao0_in_tpdm_swao_0: endpoint {
					slave-mode;
					remote-endpoint =
					<&tpdm_swao_0_out_tpda_swao0>;
				};
			};

			port@2 {
				reg = <1>;
				tpda_swao1_in_tpdm_swao_1: endpoint {
					slave-mode;
					remote-endpoint =
					<&tpdm_swao_1_out_tpda_swao1>;
				};
			};

		};
	};

	funnel_swao: funnel@6b04000 {
		compatible = "arm,primecell";
		arm,primecell-periphid = <0x0003b908>;
		reg = <0x6b04000 0x1000>;
		reg-names = "funnel-base";

		coresight-name = "coresight-funnel-swao";

		clocks = <&clock_aop QDSS_CLK>;
		clock-names = "apb_pclk";
		ports {
			#address-cells = <1>;
			#size-cells = <0>;
			port@0 {
				reg = <0>;
				funnel_swao_out_tmc_etf: endpoint {
					remote-endpoint =
					<&tmc_etf_in_funnel_swao>;
				};
			};

			port@1 {
				reg = <5>;
				funnel_swao_in_audio_etm0: endpoint {
					slave-mode;
					remote-endpoint =
					<&audio_etm0_out_funnel_swao>;
				};
			};

			port@2 {
				reg = <5>;
				funnel_swao_in_tpdm_lpass_lpi: endpoint {
					slave-mode;
					remote-endpoint =
					<&tpdm_lpss_lpi_out_funnel_swao>;
					};
			};

			port@3 {
				reg = <6>;
				funnel_swao_in_tpda_swao: endpoint {
					slave-mode;
					remote-endpoint =
					<&tpda_swao_out_funnel_swao>;
				};
			};

			port@4 {
				reg = <7>;
				funnel_swao_in_funnel_merge: endpoint {
					slave-mode;
					remote-endpoint =
					<&funnel_merge_out_funnel_swao>;
				};
			};

		};
	};

	tmc_etf: tmc@6b05000 {
		compatible = "arm,primecell";
		arm,primecell-periphid = <0x0003b961>;
		reg = <0x6b05000 0x1000>;
		reg-names = "tmc-base";

		coresight-csr = <&csr>;
		coresight-name = "coresight-tmc-etf";

		clocks = <&clock_aop QDSS_CLK>;
		clock-names = "apb_pclk";
		ports {
			#address-cells = <1>;
			#size-cells = <0>;
			port@0 {
				reg = <0>;
				tmc_etf_out_replicator_swao: endpoint {
					remote-endpoint =
					<&replicator_swao_in_tmc_etf>;
				};
			};

			port@1 {
				reg = <0>;
				tmc_etf_in_funnel_swao: endpoint {
					slave-mode;
					remote-endpoint =
					<&funnel_swao_out_tmc_etf>;
				};
			};

		};
	};

	replicator_swao: replicator@6b06000 {
		compatible = "arm,primecell";
		arm,primecell-periphid = <0x0003b909>;
		reg = <0x6b06000 0x1000>;
		reg-names = "replicator-base";

		coresight-name = "coresight-replicator-swao";

		clocks = <&clock_aop QDSS_CLK>;
		clock-names = "apb_pclk";
		ports {
			#address-cells = <1>;
			#size-cells = <0>;
			port@0 {
				reg = <0>;
				replicator_swao_out_replicator_qdss: endpoint {
					remote-endpoint =
					<&replicator_qdss_in_replicator_swao>;
				};
			};

			port@1 {
				reg = <1>;
				replicator_swao_out_eud: endpoint {
					remote-endpoint =
					  <&eud_in_replicator_swao>;
				};
			};

			port@2 {
				reg = <0>;
				replicator_swao_in_tmc_etf: endpoint {
					slave-mode;
					remote-endpoint =
					<&tmc_etf_out_replicator_swao>;
				};
			};

		};
	};

	replicator_qdss: replicator@6046000 {
		compatible = "arm,primecell";
		arm,primecell-periphid = <0x0003b909>;
		reg = <0x6046000 0x1000>;
		reg-names = "replicator-base";

		coresight-name = "coresight-replicator-qdss";

		clocks = <&clock_aop QDSS_CLK>;
		clock-names = "apb_pclk";
		ports {
			#address-cells = <1>;
			#size-cells = <0>;
			port@0 {
				reg = <0>;
				replicator_qdss_out_tmc_etr: endpoint {
					remote-endpoint =
					<&tmc_etr_in_replicator_qdss>;
				};
			};

			port@1 {
				reg = <0>;
				replicator_qdss_in_replicator_swao: endpoint {
					slave-mode;
					remote-endpoint =
					<&replicator_swao_out_replicator_qdss>;
				};
			};

		};
	};

	tmc_etr: tmc@6048000 {
		compatible = "arm,primecell";
		arm,primecell-periphid = <0x0003b961>;
		reg = <0x6048000 0x1000>,
			<0x6064000 0x15000>;
		reg-names = "tmc-base", "bam-base";

		iommus = <&apps_smmu 0x04a0 0x20>,
				<&apps_smmu 0x0480 0x20>;

		coresight-ctis = <&cti0 &cti0>;
		coresight-csr = <&csr>;
		coresight-name = "coresight-tmc-etr";
		arm,buffer-size = <0x400000>;

		clocks = <&clock_aop QDSS_CLK>;
		clock-names = "apb_pclk";

		interrupts = <GIC_SPI 270 IRQ_TYPE_EDGE_RISING>;
		interrupt-names = "byte-cntr-irq";

		port {
			tmc_etr_in_replicator_qdss: endpoint {
				slave-mode;
				remote-endpoint =
				<&replicator_qdss_out_tmc_etr>;
			};
		};
	};

	cti_apss_cti0: cti@78e0000 {
		compatible = "arm,primecell";
		arm,primecell-periphid = <0x0003b966>;
		reg = <0x78e0000 0x1000>;
		reg-names = "cti-base";

		coresight-name = "coresight-cti-apss_cti0";

		clocks = <&clock_aop QDSS_CLK>;
		clock-names = "apb_pclk";
	};

	cti_apss_cti1: cti@78f0000 {
		compatible = "arm,primecell";
		arm,primecell-periphid = <0x0003b966>;
		reg = <0x78f0000 0x1000>;
		reg-names = "cti-base";

		coresight-name = "coresight-cti-apss_cti1";

		clocks = <&clock_aop QDSS_CLK>;
		clock-names = "apb_pclk";
	};

	cti_apss_cti2: cti@7900000 {
		compatible = "arm,primecell";
		arm,primecell-periphid = <0x0003b966>;
		reg = <0x7900000 0x1000>;
		reg-names = "cti-base";

		coresight-name = "coresight-cti-apss_cti2";

		clocks = <&clock_aop QDSS_CLK>;
		clock-names = "apb_pclk";
	};

	cti0: cti@6010000 {
		compatible = "arm,primecell";
		arm,primecell-periphid = <0x0003b966>;
		reg = <0x6010000 0x1000>;
		reg-names = "cti-base";

		coresight-name = "coresight-cti0";

		clocks = <&clock_aop QDSS_CLK>;
		clock-names = "apb_pclk";
	};

	cti1: cti@6011000 {
		compatible = "arm,primecell";
		arm,primecell-periphid = <0x0003b966>;
		reg = <0x6011000 0x1000>;
		reg-names = "cti-base";

		coresight-name = "coresight-cti1";

		clocks = <&clock_aop QDSS_CLK>;
		clock-names = "apb_pclk";
	};

	cti10: cti@601a000 {
		compatible = "arm,primecell";
		arm,primecell-periphid = <0x0003b966>;
		reg = <0x601a000 0x1000>;
		reg-names = "cti-base";

		coresight-name = "coresight-cti10";

		clocks = <&clock_aop QDSS_CLK>;
		clock-names = "apb_pclk";
	};

	cti11: cti@601b000 {
		compatible = "arm,primecell";
		arm,primecell-periphid = <0x0003b966>;
		reg = <0x601b000 0x1000>;
		reg-names = "cti-base";

		coresight-name = "coresight-cti11";

		clocks = <&clock_aop QDSS_CLK>;
		clock-names = "apb_pclk";
	};

	cti12: cti@601c000 {
		compatible = "arm,primecell";
		arm,primecell-periphid = <0x0003b966>;
		reg = <0x601c000 0x1000>;
		reg-names = "cti-base";

		coresight-name = "coresight-cti12";

		clocks = <&clock_aop QDSS_CLK>;
		clock-names = "apb_pclk";
	};

	cti13: cti@601d000 {
		compatible = "arm,primecell";
		arm,primecell-periphid = <0x0003b966>;
		reg = <0x601d000 0x1000>;
		reg-names = "cti-base";

		coresight-name = "coresight-cti13";

		clocks = <&clock_aop QDSS_CLK>;
		clock-names = "apb_pclk";
	};

	cti14: cti@601e000 {
		compatible = "arm,primecell";
		arm,primecell-periphid = <0x0003b966>;
		reg = <0x601e000 0x1000>;
		reg-names = "cti-base";

		coresight-name = "coresight-cti14";

		clocks = <&clock_aop QDSS_CLK>;
		clock-names = "apb_pclk";
	};

	cti15: cti@601f000 {
		compatible = "arm,primecell";
		arm,primecell-periphid = <0x0003b966>;
		reg = <0x601f000 0x1000>;
		reg-names = "cti-base";

		coresight-name = "coresight-cti15";

		clocks = <&clock_aop QDSS_CLK>;
		clock-names = "apb_pclk";
	};

	cti2: cti@6012000 {
		compatible = "arm,primecell";
		arm,primecell-periphid = <0x0003b966>;
		reg = <0x6012000 0x1000>;
		reg-names = "cti-base";

		coresight-name = "coresight-cti2";

		clocks = <&clock_aop QDSS_CLK>;
		clock-names = "apb_pclk";

		qcom,cti-gpio-trigout = <4>;
		pinctrl-names = "cti-trigout-pctrl";
		pinctrl-0 = <&trigout_a>;
	};

	cti3: cti@6013000 {
		compatible = "arm,primecell";
		arm,primecell-periphid = <0x0003b966>;
		reg = <0x6013000 0x1000>;
		reg-names = "cti-base";

		coresight-name = "coresight-cti3";

		clocks = <&clock_aop QDSS_CLK>;
		clock-names = "apb_pclk";
	};

	cti4: cti@6014000 {
		compatible = "arm,primecell";
		arm,primecell-periphid = <0x0003b966>;
		reg = <0x6014000 0x1000>;
		reg-names = "cti-base";

		coresight-name = "coresight-cti4";

		clocks = <&clock_aop QDSS_CLK>;
		clock-names = "apb_pclk";
	};

	cti5: cti@6015000 {
		compatible = "arm,primecell";
		arm,primecell-periphid = <0x0003b966>;
		reg = <0x6015000 0x1000>;
		reg-names = "cti-base";

		coresight-name = "coresight-cti5";

		clocks = <&clock_aop QDSS_CLK>;
		clock-names = "apb_pclk";
	};

	cti6: cti@6016000 {
		compatible = "arm,primecell";
		arm,primecell-periphid = <0x0003b966>;
		reg = <0x6016000 0x1000>;
		reg-names = "cti-base";

		coresight-name = "coresight-cti6";

		clocks = <&clock_aop QDSS_CLK>;
		clock-names = "apb_pclk";
	};

	cti7: cti@6017000 {
		compatible = "arm,primecell";
		arm,primecell-periphid = <0x0003b966>;
		reg = <0x6017000 0x1000>;
		reg-names = "cti-base";

		coresight-name = "coresight-cti7";

		clocks = <&clock_aop QDSS_CLK>;
		clock-names = "apb_pclk";
	};

	cti8: cti@6018000 {
		compatible = "arm,primecell";
		arm,primecell-periphid = <0x0003b966>;
		reg = <0x6018000 0x1000>;
		reg-names = "cti-base";

		coresight-name = "coresight-cti8";

		clocks = <&clock_aop QDSS_CLK>;
		clock-names = "apb_pclk";
	};

	cti9: cti@6019000 {
		compatible = "arm,primecell";
		arm,primecell-periphid = <0x0003b966>;
		reg = <0x6019000 0x1000>;
		reg-names = "cti-base";

		coresight-name = "coresight-cti9";

		clocks = <&clock_aop QDSS_CLK>;
		clock-names = "apb_pclk";
	};

	cti_mss: cti@680b000 {
		compatible = "arm,primecell";
		arm,primecell-periphid = <0x0003b966>;
		reg = <0x680b000 0x1000>;
		reg-names = "cti-base";

		coresight-name = "coresight-cti-mss_q6";

		clocks = <&clock_aop QDSS_CLK>;
		clock-names = "apb_pclk";
	};

	cti_venus: cti@6830000 {
		compatible = "arm,primecell";
		arm,primecell-periphid = <0x0003b966>;
		reg = <0x6830000 0x1000>;
		reg-names = "cti-base";

		coresight-name = "coresight-cti-arm9";

		clocks = <&clock_aop QDSS_CLK>;
		clock-names = "apb_pclk";
	};

	cti_lpass_dl_cti: cti@6845000 {
		compatible = "arm,primecell";
		arm,primecell-periphid = <0x0003b966>;
		reg = <0x6845000 0x1000>;
		reg-names = "cti-base";

		coresight-name = "coresight-cti-lpass_dl_cti";

		clocks = <&clock_aop QDSS_CLK>;
		clock-names = "apb_pclk";
	};

	cti_gpu_isdb_cti: cti@6941000 {
		compatible = "arm,primecell";
		arm,primecell-periphid = <0x0003b966>;
		reg = <0x6941000 0x1000>;
		reg-names = "cti-base";

		status = "disabled";
		coresight-name = "coresight-cti-gpu_isdb_cti";

		clocks = <&clock_aop QDSS_CLK>;
		clock-names = "apb_pclk";
	};

	cti_gpu_cortex_m3: cti@6942000 {
		compatible = "arm,primecell";
		arm,primecell-periphid = <0x0003b966>;
		reg = <0x6942000 0x1000>;
		reg-names = "cti-base";

		status = "disabled";
		coresight-name = "coresight-cti-gpu_cortex_m3";

		clocks = <&clock_aop QDSS_CLK>;
		clock-names = "apb_pclk";
	};

	cti_turing_dl_cti: cti@6982000 {
		compatible = "arm,primecell";
		arm,primecell-periphid = <0x0003b966>;
		reg = <0x6982000 0x1000>;
		reg-names = "cti-base";

		coresight-name = "coresight-cti-turing_dl_cti";

		clocks = <&clock_aop QDSS_CLK>;
		clock-names = "apb_pclk";
	};

	cti_turing_q6_cti: cti@698b000 {
		compatible = "arm,primecell";
		arm,primecell-periphid = <0x0003b966>;
		reg = <0x698b000 0x1000>;
		reg-names = "cti-base";

		coresight-name = "coresight-cti-turing_q6_cti";

		clocks = <&clock_aop QDSS_CLK>;
		clock-names = "apb_pclk";
	};

	cti_dl_north_cti0: cti@6ac1000 {
		compatible = "arm,primecell";
		arm,primecell-periphid = <0x0003b966>;
		reg = <0x6ac1000 0x1000>;
		reg-names = "cti-base";

		coresight-name = "coresight-cti-dlnt_cti0";

		clocks = <&clock_aop QDSS_CLK>;
		clock-names = "apb_pclk";
	};

	cti_dl_north_cti1: cti@6ac2000 {
		compatible = "arm,primecell";
		arm,primecell-periphid = <0x0003b966>;
		reg = <0x6ac2000 0x1000>;
		reg-names = "cti-base";

		coresight-name = "coresight-cti-dlnt_cti1";

		clocks = <&clock_aop QDSS_CLK>;
		clock-names = "apb_pclk";
	};

	cti_dl_north_cti2: cti@6ac3000 {
		compatible = "arm,primecell";
		arm,primecell-periphid = <0x0003b966>;
		reg = <0x6ac3000 0x1000>;
		reg-names = "cti-base";

		coresight-name = "coresight-cti-dlnt_cti2";

		clocks = <&clock_aop QDSS_CLK>;
		clock-names = "apb_pclk";
	};

	cti_dl_north_cti3: cti@6ac4000 {
		compatible = "arm,primecell";
		arm,primecell-periphid = <0x0003b966>;
		reg = <0x6ac4000 0x1000>;
		reg-names = "cti-base";

		coresight-name = "coresight-cti-dlnt_cti3";

		clocks = <&clock_aop QDSS_CLK>;
		clock-names = "apb_pclk";
	};

	cti_swao_cti0: cti@6b00000 {
		compatible = "arm,primecell";
		arm,primecell-periphid = <0x0003b966>;
		reg = <0x6b00000 0x1000>;
		reg-names = "cti-base";

		coresight-name = "coresight-cti-swao_cti0";

		clocks = <&clock_aop QDSS_CLK>;
		clock-names = "apb_pclk";
	};

	cti_swao_cti1: cti@6b01000 {
		compatible = "arm,primecell";
		arm,primecell-periphid = <0x0003b966>;
		reg = <0x6b01000 0x1000>;
		reg-names = "cti-base";

		coresight-name = "coresight-cti-swao_cti1";

		clocks = <&clock_aop QDSS_CLK>;
		clock-names = "apb_pclk";
	};

	cti_swao_cti2: cti@6b02000 {
		compatible = "arm,primecell";
		arm,primecell-periphid = <0x0003b966>;
		reg = <0x6b02000 0x1000>;
		reg-names = "cti-base";

		coresight-name = "coresight-cti-swao_cti2";

		clocks = <&clock_aop QDSS_CLK>;
		clock-names = "apb_pclk";
	};

	cti_swao_cti3: cti@6b03000 {
		compatible = "arm,primecell";
		arm,primecell-periphid = <0x0003b966>;
		reg = <0x6b03000 0x1000>;
		reg-names = "cti-base";

		coresight-name = "coresight-cti-swao_cti3";

		clocks = <&clock_aop QDSS_CLK>;
		clock-names = "apb_pclk";
	};

	cti_aop_m3: cti@6b0e000 {
		compatible = "arm,primecell";
		arm,primecell-periphid = <0x0003b966>;
		reg = <0x6b0e000 0x1000>;
		reg-names = "cti-base";

		coresight-name = "coresight-cti-cortex_m3";

		clocks = <&clock_aop QDSS_CLK>;
		clock-names = "apb_pclk";
	};

	cti_lpass_lpi_cti: cti@6b21000 {
		compatible = "arm,primecell";
		arm,primecell-periphid = <0x0003b966>;
		reg = <0x6b21000 0x1000>;
		reg-names = "cti-base";

		status = "disabled";

		coresight-name = "coresight-cti-lpass_lpi_cti";

		clocks = <&clock_aop QDSS_CLK>;
		clock-names = "apb_pclk";
	};

	cti_lpass_q6_cti: cti@6b2B000 {
		compatible = "arm,primecell";
		arm,primecell-periphid = <0x0003b966>;
		reg = <0x6b2B000 0x1000>;
		reg-names = "cti-base";

		status = "disabled";
		coresight-name = "coresight-cti-lpass_q6_cti";

		clocks = <&clock_aop QDSS_CLK>;
		clock-names = "apb_pclk";
	};

	cti_dlct_cti0: cti@6c2a000 {
		compatible = "arm,primecell";
		arm,primecell-periphid = <0x0003b966>;
		reg = <0x6c2a000 0x1000>;
		reg-names = "cti-base";

		coresight-name = "coresight-cti-dlct0_cti0";

		clocks = <&clock_aop QDSS_CLK>;
		clock-names = "apb_pclk";
	};

	cti_dlct_cti1: cti@6C2b000 {
		compatible = "arm,primecell";
		arm,primecell-periphid = <0x0003b966>;
		reg = <0x6C2b000 0x1000>;
		reg-names = "cti-base";

		coresight-name = "coresight-cti-dlct0_cti1";

		clocks = <&clock_aop QDSS_CLK>;
		clock-names = "apb_pclk";
	};

	cti_dlct_cti2: cti@6c2c000 {
		compatible = "arm,primecell";
		arm,primecell-periphid = <0x0003b966>;
		reg = <0x6c2c000 0x1000>;
		reg-names = "cti-base";

		coresight-name = "coresight-cti-dlct0_cti2";

		clocks = <&clock_aop QDSS_CLK>;
		clock-names = "apb_pclk";
	};

	cti_npu_dl_cti_0: cti@6c42000 {
		compatible = "arm,primecell";
		arm,primecell-periphid = <0x0003b966>;
		reg = <0x6c42000 0x1000>;
		reg-names = "cti-base";

		coresight-name = "coresight-cti-npu_dl_cti_0";

		clocks = <&clock_aop QDSS_CLK>;
		clock-names = "apb_pclk";
	};

	cti_npu_dl_cti_1: cti@6C43000 {
		compatible = "arm,primecell";
		arm,primecell-periphid = <0x0003b966>;
		reg = <0x6C43000 0x1000>;
		reg-names = "cti-base";

		coresight-name = "coresight-cti-npu_dl_cti_1";

		clocks = <&clock_aop QDSS_CLK>;
		clock-names = "apb_pclk";
	};

	cti_npu_q6_cti: cti@6C4b000 {
		compatible = "arm,primecell";
		arm,primecell-periphid = <0x0003b966>;
		reg = <0x6C4b000 0x1000>;
		reg-names = "cti-base";

		coresight-name = "coresight-cti-npu_q6_cti";

		clocks = <&clock_aop QDSS_CLK>;
		clock-names = "apb_pclk";
	};

	cti_sierra_a6_cti: cti@6c13000 {
		compatible = "arm,primecell";
		arm,primecell-periphid = <0x0003b966>;
		reg = <0x6c13000 0x1000>;
		reg-names = "cti-base";

		coresight-name = "coresight-cti-sierra_a6_cti";

		clocks = <&clock_aop QDSS_CLK>;
		clock-names = "apb_pclk";
	};

	cti_mdss_dl_cti: cti@6c61000 {
		compatible = "arm,primecell";
		arm,primecell-periphid = <0x0003b966>;
		reg = <0x6c61000 0x1000>;
		reg-names = "cti-base";

		coresight-name = "coresight-cti-mdss_dl_cti";

		clocks = <&clock_aop QDSS_CLK>;
		clock-names = "apb_pclk";
	};

	cti_ddr_dl_0_cti_0: cti@6f82000 {
		compatible = "arm,primecell";
		arm,primecell-periphid = <0x0003b966>;
		reg = <0x6f82000 0x1000>;
		reg-names = "cti-base";

		coresight-name = "coresight-cti-ddr_dl_0_cti_0";

		clocks = <&clock_aop QDSS_CLK>;
		clock-names = "apb_pclk";
	};

	cti_ddr_dl_0_cti_1: cti@6f83000 {
		compatible = "arm,primecell";
		arm,primecell-periphid = <0x0003b966>;
		reg = <0x6f83000 0x1000>;
		reg-names = "cti-base";

		coresight-name = "coresight-cti-ddr_dl_0_cti_1";

		clocks = <&clock_aop QDSS_CLK>;
		clock-names = "apb_pclk";
	};

	cti_ddr_dl_0_cti_2: cti@6f84000 {
		compatible = "arm,primecell";
		arm,primecell-periphid = <0x0003b966>;
		reg = <0x6f84000 0x1000>;
		reg-names = "cti-base";

		coresight-name = "coresight-cti-ddr_dl_0_cti_2";

		clocks = <&clock_aop QDSS_CLK>;
		clock-names = "apb_pclk";
	};

	cti_ddr_dl_1_cti_0: cti@6f90000 {
		compatible = "arm,primecell";
		arm,primecell-periphid = <0x0003b966>;
		reg = <0x6f90000 0x1000>;
		reg-names = "cti-base";

		coresight-name = "coresight-cti-ddr_dl_1_cti_0";

		clocks = <&clock_aop QDSS_CLK>;
		clock-names = "apb_pclk";
	};

	cti_ddr_dl_1_cti_1: cti@6f91000 {
		compatible = "arm,primecell";
		arm,primecell-periphid = <0x0003b966>;
		reg = <0x6f91000 0x1000>;
		reg-names = "cti-base";

		coresight-name = "coresight-cti-ddr_dl_1_cti_1";

		clocks = <&clock_aop QDSS_CLK>;
		clock-names = "apb_pclk";
	};

	cti_ddr_dl_1_cti_2: cti@6f92000 {
		compatible = "arm,primecell";
		arm,primecell-periphid = <0x0003b966>;
		reg = <0x6f92000 0x1000>;
		reg-names = "cti-base";

		coresight-name = "coresight-cti-ddr_dl_1_cti_2";

		clocks = <&clock_aop QDSS_CLK>;
		clock-names = "apb_pclk";
	};

	cti_olc: cti@7831000 {
		compatible = "arm,primecell";
		arm,primecell-periphid = <0x0003b966>;
		reg = <0x7831000 0x1000>;
		reg-names = "cti-base";

		coresight-name = "coresight-cti-olc";

		clocks = <&clock_aop QDSS_CLK>;
		clock-names = "apb_pclk";
	};

	cti_dl_apss: cti@7861000 {
		compatible = "arm,primecell";
		arm,primecell-periphid = <0x0003b966>;
		reg = <0x7861000 0x1000>;
		reg-names = "cti-base";

		coresight-name = "coresight-cti-dl-apss";

		clocks = <&clock_aop QDSS_CLK>;
		clock-names = "apb_pclk";
	};

	stm: stm@6002000 {
		compatible = "arm,primecell";
		arm,primecell-periphid = <0x0003b962>;

		reg = <0x6002000 0x1000>,
		      <0x16280000 0x180000>;
		reg-names = "stm-base", "stm-stimulus-base";

		coresight-name = "coresight-stm";

		clocks = <&clock_aop QDSS_CLK>;
		clock-names = "apb_pclk";

		port {
			stm_out_funnel_in0: endpoint {
				remote-endpoint = <&funnel_in0_in_stm>;
			};
		};

	};

	swao_csr: csr@6b0c000 {
		compatible = "qcom,coresight-csr";
		reg = <0x6b0c000 0x1000>;
		reg-names = "csr-base";

		coresight-name = "coresight-swao-csr";
		qcom,timestamp-support;

		clocks = <&clock_aop QDSS_CLK>;
		clock-names = "apb_pclk";

		qcom,blk-size = <1>;
	};

	hwevent {
		compatible = "qcom,coresight-hwevent";

		coresight-name = "coresight-hwevent";
		coresight-csr = <&csr>;
		clocks = <&clock_aop QDSS_CLK>;
		clock-names = "apb_pclk";
	};

	dummy_eud: dummy_sink {
		compatible = "qcom,coresight-dummy";

		coresight-name = "coresight-eud";

		qcom,dummy-sink;
		port {
			eud_in_replicator_swao: endpoint {
				slave-mode;
				remote-endpoint =
				<&replicator_swao_out_eud>;
			};
		};
	};

	ipcb_tgu: tgu@6b0b000 {
		compatible = "arm,primecell";
		arm,primecell-periphid = <0x0003b999>;
		reg = <0x06b0b000 0x1000>;
		reg-names = "tgu-base";
		tgu-steps = <3>;
		tgu-conditions = <4>;
		tgu-regs = <4>;
		tgu-timer-counters = <8>;

		coresight-name = "coresight-tgu-ipcb";

		clocks = <&clock_aop QDSS_CLK>;
		clock-names = "apb_pclk";
	};
};
